# ing916 register map
Vendor: INGChips; Series: ing916xx; File version: 522
CPU: CM4 r0p1, little endian, MPU, FPU, VTOR, 5 interrupt priority bits
Registers are 32-bit, read-write, reset 0x0 unless marked. A register's access mark holds for its fields unless they carry their own. Offsets are from the block's base; [hi:lo] are bit positions; {n}, {i} and the like mark numbered series.

## usbc
Base 0x40180000
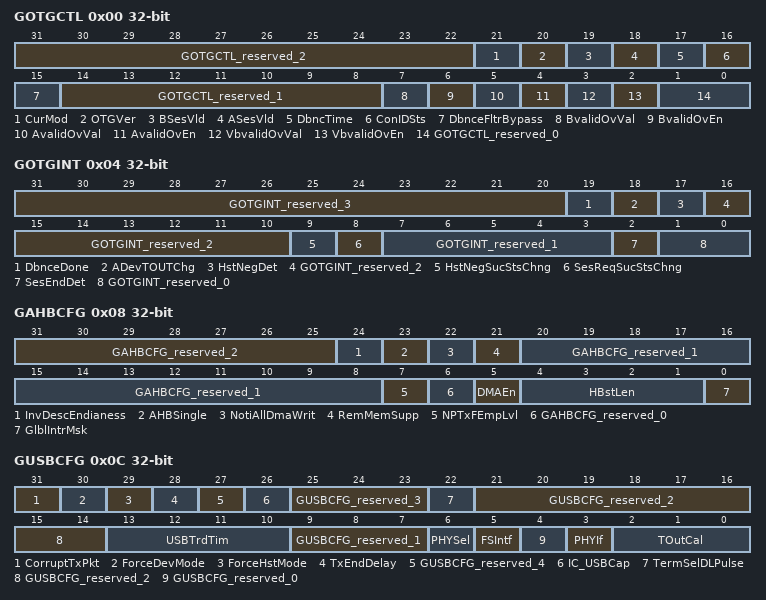
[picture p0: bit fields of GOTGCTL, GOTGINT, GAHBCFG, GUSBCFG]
0x00 GOTGCTL — reg description:
  [31:22] GOTGCTL_reserved_2 — reg description:
  [21] CurMod — reg description:
  [20] OTGVer — reg description:
  [19] BSesVld — reg description:
  [18] ASesVld — reg description:
  [17] DbncTime — reg description:
  [16] ConIDSts — reg description:
  [15] DbnceFltrBypass — reg description:
  [14:8] GOTGCTL_reserved_1 — reg description:
  [7] BvalidOvVal — reg description:
  [6] BvalidOvEn — reg description:
  [5] AvalidOvVal — reg description:
  [4] AvalidOvEn — reg description:
  [3] VbvalidOvVal — reg description:
  [2] VbvalidOvEn — reg description:
  [1:0] GOTGCTL_reserved_0 — reg description:
0x04 GOTGINT — reg description:
  [31:20] GOTGINT_reserved_3 — reg description:
  [19] DbnceDone — reg description:
  [18] ADevTOUTChg — reg description:
  [17] HstNegDet — reg description:
  [16:10] GOTGINT_reserved_2 — reg description:
  [9] HstNegSucStsChng — reg description:
  [8] SesReqSucStsChng — reg description:
  [7:3] GOTGINT_reserved_1 — reg description:
  [2] SesEndDet — reg description:
  [1:0] GOTGINT_reserved_0 — reg description:
0x08 GAHBCFG — reg description:
  [31:25] GAHBCFG_reserved_2 — reg description:
  [24] InvDescEndianess — reg description:
  [23] AHBSingle — reg description:
  [22] NotiAllDmaWrit — reg description:
  [21] RemMemSupp — reg description:
  [20:8] GAHBCFG_reserved_1 — reg description:
  [7] NPTxFEmpLvl — reg description:
  [6] GAHBCFG_reserved_0 — reg description:
  [5] DMAEn — reg description:
  [4:1] HBstLen — reg description:
  [0] GlblIntrMsk — reg description:
0x0C GUSBCFG — reg description:
  [31] CorruptTxPkt — reg description:
  [30] ForceDevMode — reg description:
  [29] ForceHstMode — reg description:
  [28] TxEndDelay — reg description:
  [27] GUSBCFG_reserved_4 — reg description:
  [26] IC_USBCap — reg description:
  [25:23] GUSBCFG_reserved_3 — reg description:
  [22] TermSelDLPulse — reg description:
  [21:14] GUSBCFG_reserved_2 — reg description:
  [13:10] USBTrdTim — reg description:
  [9:7] GUSBCFG_reserved_1 — reg description:
  [6] PHYSel — reg description:
  [5] FSIntf — reg description:
  [4] GUSBCFG_reserved_0 — reg description:
  [3] PHYIf — reg description:
  [2:0] TOutCal — reg description:
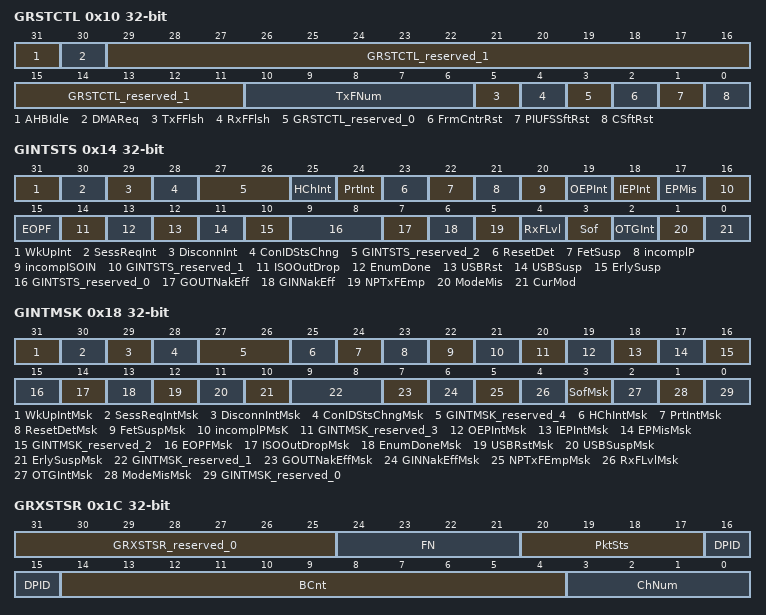
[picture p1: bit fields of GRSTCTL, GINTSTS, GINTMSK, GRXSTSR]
0x10 GRSTCTL — reg description:
  [31] AHBIdle — reg description:
  [30] DMAReq — reg description:
  [29:11] GRSTCTL_reserved_1 — reg description:
  [10:6] TxFNum — reg description:
  [5] TxFFlsh — reg description:
  [4] RxFFlsh — reg description:
  [3] GRSTCTL_reserved_0 — reg description:
  [2] FrmCntrRst — reg description:
  [1] PIUFSSftRst — reg description:
  [0] CSftRst — reg description:
0x14 GINTSTS — reg description:
  [31] WkUpInt — reg description:
  [30] SessReqInt — reg description:
  [29] DisconnInt — reg description:
  [28] ConIDStsChng — reg description:
  [27:26] GINTSTS_reserved_2 — reg description:
  [25] HChInt — reg description:
  [24] PrtInt — reg description:
  [23] ResetDet — reg description:
  [22] FetSusp — reg description:
  [21] incomplP — reg description:
  [20] incompISOIN — reg description:
  [19] OEPInt — reg description:
  [18] IEPInt — reg description:
  [17] EPMis — reg description:
  [16] GINTSTS_reserved_1 — reg description:
  [15] EOPF — reg description:
  [14] ISOOutDrop — reg description:
  [13] EnumDone — reg description:
  [12] USBRst — reg description:
  [11] USBSusp — reg description:
  [10] ErlySusp — reg description:
  [9:8] GINTSTS_reserved_0 — reg description:
  [7] GOUTNakEff — reg description:
  [6] GINNakEff — reg description:
  [5] NPTxFEmp — reg description:
  [4] RxFLvl — reg description:
  [3] Sof — reg description:
  [2] OTGInt — reg description:
  [1] ModeMis — reg description:
  [0] CurMod — reg description:
0x18 GINTMSK — reg description:
  [31] WkUpIntMsk — reg description:
  [30] SessReqIntMsk — reg description:
  [29] DisconnIntMsk — reg description:
  [28] ConIDStsChngMsk — reg description:
  [27:26] GINTMSK_reserved_4 — reg description:
  [25] HChIntMsk — reg description:
  [24] PrtIntMsk — reg description:
  [23] ResetDetMsk — reg description:
  [22] FetSuspMsk — reg description:
  [21] incomplPMsK — reg description:
  [20] GINTMSK_reserved_3 — reg description:
  [19] OEPIntMsk — reg description:
  [18] IEPIntMsk — reg description:
  [17] EPMisMsk — reg description:
  [16] GINTMSK_reserved_2 — reg description:
  [15] EOPFMsk — reg description:
  [14] ISOOutDropMsk — reg description:
  [13] EnumDoneMsk — reg description:
  [12] USBRstMsk — reg description:
  [11] USBSuspMsk — reg description:
  [10] ErlySuspMsk — reg description:
  [9:8] GINTMSK_reserved_1 — reg description:
  [7] GOUTNakEffMsk — reg description:
  [6] GINNakEffMsk — reg description:
  [5] NPTxFEmpMsk — reg description:
  [4] RxFLvlMsk — reg description:
  [3] SofMsk — reg description:
  [2] OTGIntMsk — reg description:
  [1] ModeMisMsk — reg description:
  [0] GINTMSK_reserved_0 — reg description:
0x1C GRXSTSR — reg description:
  [31:25] GRXSTSR_reserved_0 — reg description:
  [24:21] FN — reg description:
  [20:17] PktSts — reg description:
  [16:15] DPID — reg description:
  [14:4] BCnt — reg description:
  [3:0] ChNum — reg description:
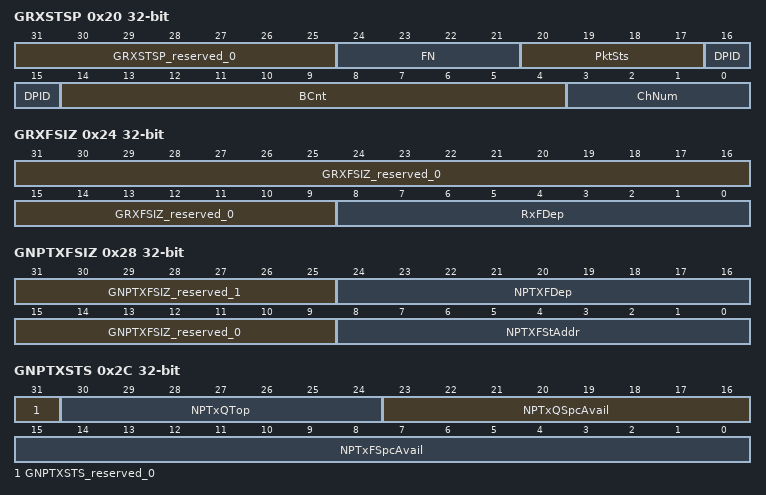
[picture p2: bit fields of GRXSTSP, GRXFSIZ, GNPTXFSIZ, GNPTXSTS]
0x20 GRXSTSP — reg description:
  [31:25] GRXSTSP_reserved_0 — reg description:
  [24:21] FN — reg description:
  [20:17] PktSts — reg description:
  [16:15] DPID — reg description:
  [14:4] BCnt — reg description:
  [3:0] ChNum — reg description:
0x24 GRXFSIZ — reg description:
  [31:9] GRXFSIZ_reserved_0 — reg description:
  [8:0] RxFDep — reg description:
0x28 GNPTXFSIZ — reg description:
  [31:25] GNPTXFSIZ_reserved_1 — reg description:
  [24:16] NPTXFDep — reg description:
  [15:9] GNPTXFSIZ_reserved_0 — reg description:
  [8:0] NPTXFStAddr — reg description:
0x2C GNPTXSTS — reg description:
  [31] GNPTXSTS_reserved_0 — reg description:
  [30:24] NPTxQTop — reg description:
  [23:16] NPTxQSpcAvail — reg description:
  [15:0] NPTxFSpcAvail — reg description:
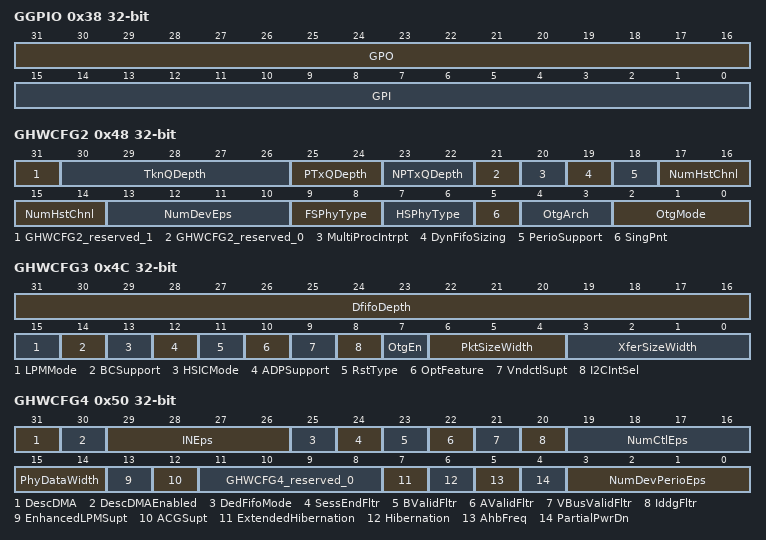
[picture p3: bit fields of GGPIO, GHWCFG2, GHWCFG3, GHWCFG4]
0x38 GGPIO — reg description:
  [31:16] GPO — reg description:
  [15:0] GPI — reg description:
0x3C GUID — reg description:
0x40 GSNPSID — reg description:
  [31:0] SynopsysID
0x44 GHWCFG1 — reg description:
  [31:0] EpDir
0x48 GHWCFG2 — reg description:
  [31] GHWCFG2_reserved_1 — reg description:
  [30:26] TknQDepth — reg description:
  [25:24] PTxQDepth — reg description:
  [23:22] NPTxQDepth — reg description:
  [21] GHWCFG2_reserved_0 — reg description:
  [20] MultiProcIntrpt — reg description:
  [19] DynFifoSizing — reg description:
  [18] PerioSupport — reg description:
  [17:14] NumHstChnl — reg description:
  [13:10] NumDevEps — reg description:
  [9:8] FSPhyType — reg description:
  [7:6] HSPhyType — reg description:
  [5] SingPnt — reg description:
  [4:3] OtgArch — reg description:
  [2:0] OtgMode — reg description:
0x4C GHWCFG3 — reg description:
  [31:16] DfifoDepth — reg description:
  [15] LPMMode — reg description:
  [14] BCSupport — reg description:
  [13] HSICMode — reg description:
  [12] ADPSupport — reg description:
  [11] RstType — reg description:
  [10] OptFeature — reg description:
  [9] VndctlSupt — reg description:
  [8] I2CIntSel — reg description:
  [7] OtgEn — reg description:
  [6:4] PktSizeWidth — reg description:
  [3:0] XferSizeWidth — reg description:
0x50 GHWCFG4 — reg description:
  [31] DescDMA — reg description:
  [30] DescDMAEnabled — reg description:
  [29:26] INEps — reg description:
  [25] DedFifoMode — reg description:
  [24] SessEndFltr — reg description:
  [23] BValidFltr — reg description:
  [22] AValidFltr — reg description:
  [21] VBusValidFltr — reg description:
  [20] IddgFltr — reg description:
  [19:16] NumCtlEps — reg description:
  [15:14] PhyDataWidth — reg description:
  [13] EnhancedLPMSupt — reg description:
  [12] ACGSupt — reg description:
  [11:8] GHWCFG4_reserved_0 — reg description:
  [7] ExtendedHibernation — reg description:
  [6] Hibernation — reg description:
  [5] AhbFreq — reg description:
  [4] PartialPwrDn — reg description:
  [3:0] NumDevPerioEps — reg description:
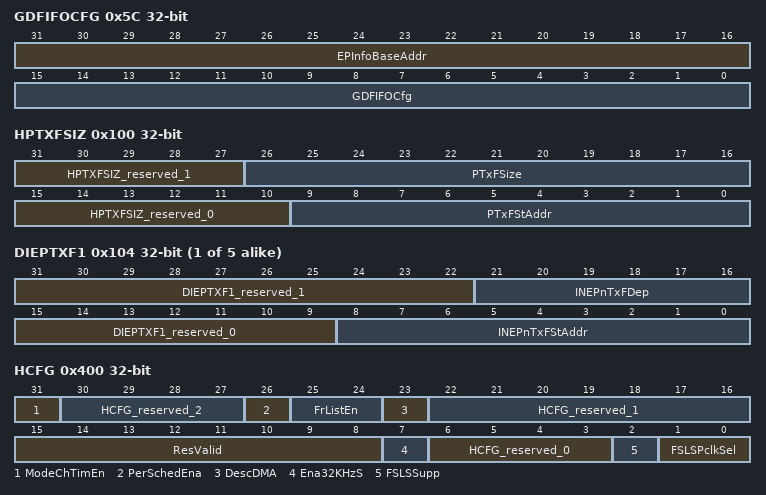
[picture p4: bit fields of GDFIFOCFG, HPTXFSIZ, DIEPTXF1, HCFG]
0x5C GDFIFOCFG — reg description:
  [31:16] EPInfoBaseAddr — reg description:
  [15:0] GDFIFOCfg — reg description:
0x100 HPTXFSIZ — reg description:
  [31:27] HPTXFSIZ_reserved_1 — reg description:
  [26:16] PTxFSize — reg description:
  [15:10] HPTXFSIZ_reserved_0 — reg description:
  [9:0] PTxFStAddr — reg description:
{0x100+4i} DIEPTXF{i} (i=1..5) — reg description:
  [31:22] DIEPTXF{i}_reserved_1 — reg description:
  [21:16] INEPnTxFDep — reg description:
  [15:9] DIEPTXF{i}_reserved_0 — reg description:
  [8:0] INEPnTxFStAddr — reg description:
0x400 HCFG — reg description:
  [31] ModeChTimEn — reg description:
  [30:27] HCFG_reserved_2 — reg description:
  [26] PerSchedEna — reg description:
  [25:24] FrListEn — reg description:
  [23] DescDMA — reg description:
  [22:16] HCFG_reserved_1 — reg description:
  [15:8] ResValid — reg description:
  [7] Ena32KHzS — reg description:
  [6:3] HCFG_reserved_0 — reg description:
  [2] FSLSSupp — reg description:
  [1:0] FSLSPclkSel — reg description:
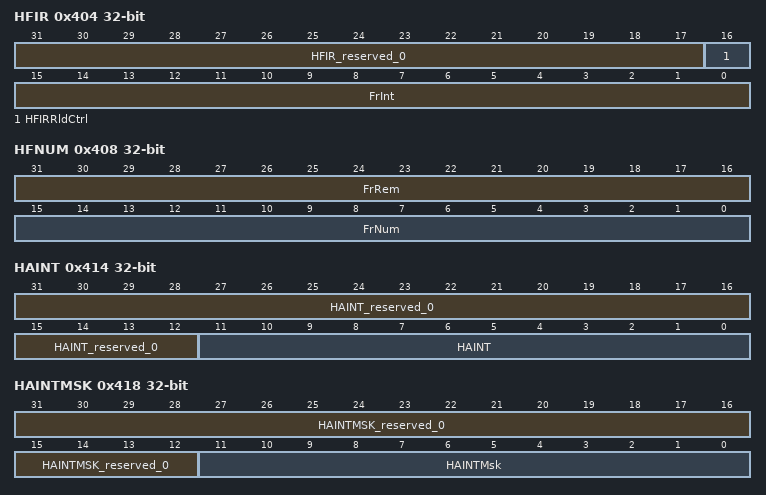
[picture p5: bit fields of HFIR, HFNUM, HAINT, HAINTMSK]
0x404 HFIR — reg description:
  [31:17] HFIR_reserved_0 — reg description:
  [16] HFIRRldCtrl — reg description:
  [15:0] FrInt — reg description:
0x408 HFNUM — reg description:
  [31:16] FrRem — reg description:
  [15:0] FrNum — reg description:
0x414 HAINT — reg description:
  [31:12] HAINT_reserved_0 — reg description:
  [11:0] HAINT — reg description:
0x418 HAINTMSK — reg description:
  [31:12] HAINTMSK_reserved_0 — reg description:
  [11:0] HAINTMsk — reg description:
0x41C HFLBAddr — reg description:
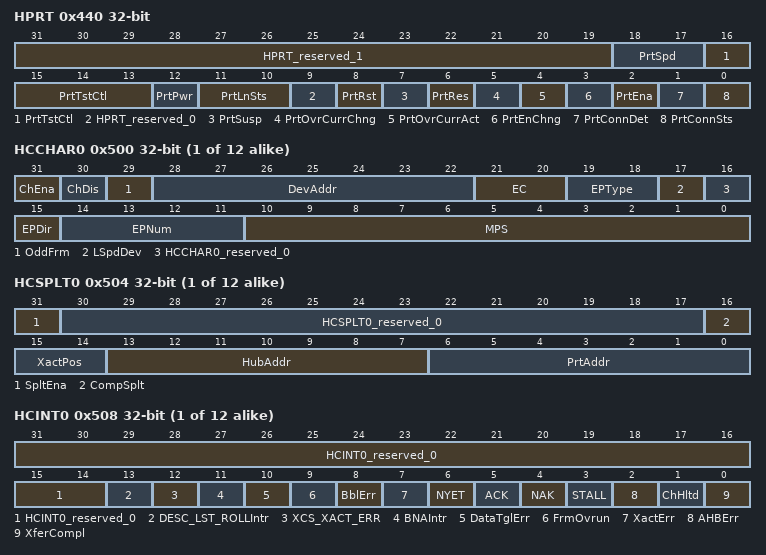
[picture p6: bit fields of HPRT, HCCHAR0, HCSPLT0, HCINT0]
0x440 HPRT — reg description:
  [31:19] HPRT_reserved_1 — reg description:
  [18:17] PrtSpd — reg description:
  [16:13] PrtTstCtl — reg description:
  [12] PrtPwr — reg description:
  [11:10] PrtLnSts — reg description:
  [9] HPRT_reserved_0 — reg description:
  [8] PrtRst — reg description:
  [7] PrtSusp — reg description:
  [6] PrtRes — reg description:
  [5] PrtOvrCurrChng — reg description:
  [4] PrtOvrCurrAct — reg description:
  [3] PrtEnChng — reg description:
  [2] PrtEna — reg description:
  [1] PrtConnDet — reg description:
  [0] PrtConnSts — reg description:
{0x500+0x20*i} HCCHAR{i} (i=0..11) — reg description:
  [31] ChEna — reg description:
  [30] ChDis — reg description:
  [29] OddFrm — reg description:
  [28:22] DevAddr — reg description:
  [21:20] EC — reg description:
  [19:18] EPType — reg description:
  [17] LSpdDev — reg description:
  [16] HCCHAR{i}_reserved_0 — reg description:
  [15] EPDir — reg description:
  [14:11] EPNum — reg description:
  [10:0] MPS — reg description:
{0x504+0x20*i} HCSPLT{i} (i=0..11) — reg description:
  [31] SpltEna — reg description:
  [30:17] HCSPLT{i}_reserved_0 — reg description:
  [16] CompSplt — reg description:
  [15:14] XactPos — reg description:
  [13:7] HubAddr — reg description:
  [6:0] PrtAddr — reg description:
{0x508+0x20*i} HCINT{i} (i=0..11) — reg description:
  [31:14] HCINT{i}_reserved_0 — reg description:
  [13] DESC_LST_ROLLIntr — reg description:
  [12] XCS_XACT_ERR — reg description:
  [11] BNAIntr — reg description:
  [10] DataTglErr — reg description:
  [9] FrmOvrun — reg description:
  [8] BblErr — reg description:
  [7] XactErr — reg description:
  [6] NYET — reg description:
  [5] ACK — reg description:
  [4] NAK — reg description:
  [3] STALL — reg description:
  [2] AHBErr — reg description:
  [1] ChHltd — reg description:
  [0] XferCompl — reg description:
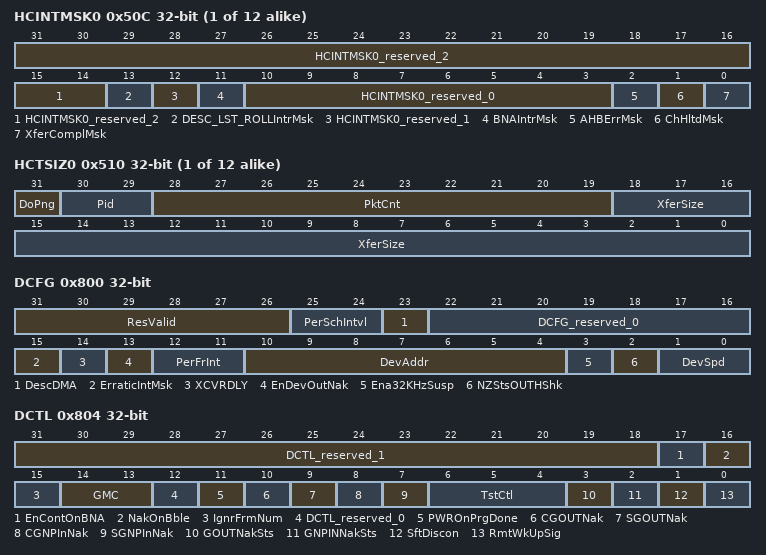
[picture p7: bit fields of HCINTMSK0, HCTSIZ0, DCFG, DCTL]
{0x50C+0x20*i} HCINTMSK{i} (i=0..11) — reg description:
  [31:14] HCINTMSK{i}_reserved_2 — reg description:
  [13] DESC_LST_ROLLIntrMsk — reg description:
  [12] HCINTMSK{i}_reserved_1 — reg description:
  [11] BNAIntrMsk — reg description:
  [10:3] HCINTMSK{i}_reserved_0 — reg description:
  [2] AHBErrMsk — reg description:
  [1] ChHltdMsk — reg description:
  [0] XferComplMsk — reg description:
{0x510+0x20*i} HCTSIZ{i} (i=0..11) — reg description:
  [31] DoPng — reg description:
  [30:29] Pid — reg description:
  [28:19] PktCnt — reg description:
  [18:0] XferSize — reg description:
{0x514+0x20*i} HCDMA{i} (i=0..11) — reg description:
  [31:0] DMAAddr
{0x51C+0x20*i} HCDMAB{i} (i=0..11) — reg description:
  [31:0] HCDMAB
0x800 DCFG — reg description:
  [31:26] ResValid — reg description:
  [25:24] PerSchIntvl — reg description:
  [23] DescDMA — reg description:
  [22:16] DCFG_reserved_0 — reg description:
  [15] ErraticIntMsk — reg description:
  [14] XCVRDLY — reg description:
  [13] EnDevOutNak — reg description:
  [12:11] PerFrInt — reg description:
  [10:4] DevAddr — reg description:
  [3] Ena32KHzSusp — reg description:
  [2] NZStsOUTHShk — reg description:
  [1:0] DevSpd — reg description:
0x804 DCTL — reg description:
  [31:18] DCTL_reserved_1 — reg description:
  [17] EnContOnBNA — reg description:
  [16] NakOnBble — reg description:
  [15] IgnrFrmNum — reg description:
  [14:13] GMC — reg description:
  [12] DCTL_reserved_0 — reg description:
  [11] PWROnPrgDone — reg description:
  [10] CGOUTNak — reg description:
  [9] SGOUTNak — reg description:
  [8] CGNPInNak — reg description:
  [7] SGNPInNak — reg description:
  [6:4] TstCtl — reg description:
  [3] GOUTNakSts — reg description:
  [2] GNPINNakSts — reg description:
  [1] SftDiscon — reg description:
  [0] RmtWkUpSig — reg description:
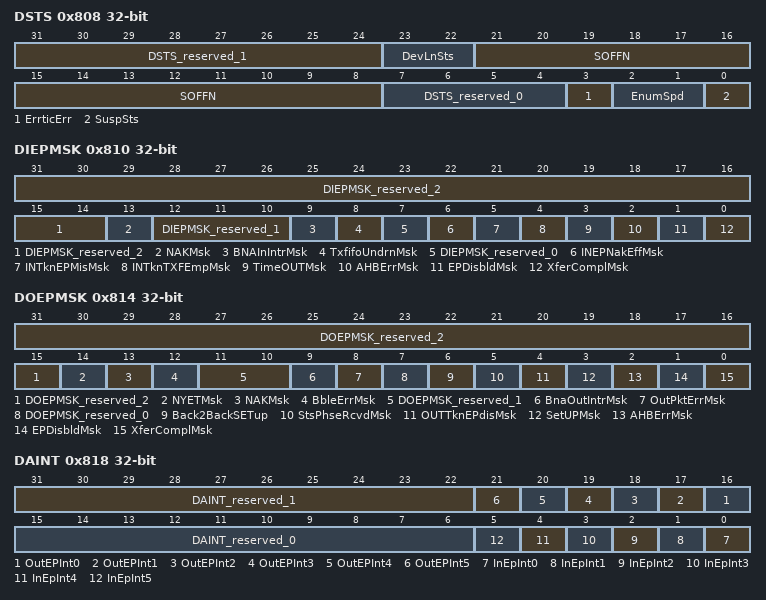
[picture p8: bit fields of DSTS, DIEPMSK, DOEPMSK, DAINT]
0x808 DSTS — reg description:
  [31:24] DSTS_reserved_1 — reg description:
  [23:22] DevLnSts — reg description:
  [21:8] SOFFN — reg description:
  [7:4] DSTS_reserved_0 — reg description:
  [3] ErrticErr — reg description:
  [2:1] EnumSpd — reg description:
  [0] SuspSts — reg description:
0x810 DIEPMSK — reg description:
  [31:14] DIEPMSK_reserved_2 — reg description:
  [13] NAKMsk — reg description:
  [12:10] DIEPMSK_reserved_1 — reg description:
  [9] BNAInIntrMsk — reg description:
  [8] TxfifoUndrnMsk — reg description:
  [7] DIEPMSK_reserved_0 — reg description:
  [6] INEPNakEffMsk — reg description:
  [5] INTknEPMisMsk — reg description:
  [4] INTknTXFEmpMsk — reg description:
  [3] TimeOUTMsk — reg description:
  [2] AHBErrMsk — reg description:
  [1] EPDisbldMsk — reg description:
  [0] XferComplMsk — reg description:
0x814 DOEPMSK — reg description:
  [31:15] DOEPMSK_reserved_2 — reg description:
  [14] NYETMsk — reg description:
  [13] NAKMsk — reg description:
  [12] BbleErrMsk — reg description:
  [11:10] DOEPMSK_reserved_1 — reg description:
  [9] BnaOutIntrMsk — reg description:
  [8] OutPktErrMsk — reg description:
  [7] DOEPMSK_reserved_0 — reg description:
  [6] Back2BackSETup — reg description:
  [5] StsPhseRcvdMsk — reg description:
  [4] OUTTknEPdisMsk — reg description:
  [3] SetUPMsk — reg description:
  [2] AHBErrMsk — reg description:
  [1] EPDisbldMsk — reg description:
  [0] XferComplMsk — reg description:
0x818 DAINT — reg description:
  [31:22] DAINT_reserved_1 — reg description:
  [n+16] OutEPInt{n} (n=0..5) — reg description:
  [15:6] DAINT_reserved_0 — reg description:
  [n] InEpInt{n} (n=0..5) — reg description:
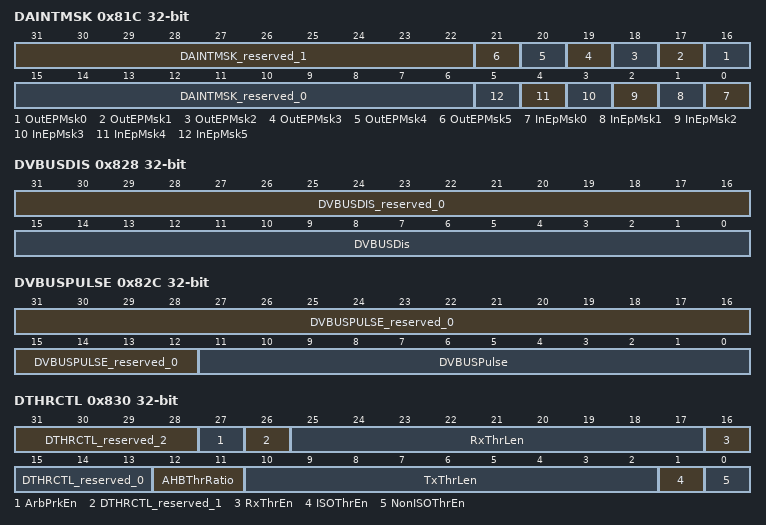
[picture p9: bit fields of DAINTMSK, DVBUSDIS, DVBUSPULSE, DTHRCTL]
0x81C DAINTMSK — reg description:
  [31:22] DAINTMSK_reserved_1 — reg description:
  [n+16] OutEPMsk{n} (n=0..5) — reg description:
  [15:6] DAINTMSK_reserved_0 — reg description:
  [n] InEpMsk{n} (n=0..5) — reg description:
0x828 DVBUSDIS — reg description:
  [31:16] DVBUSDIS_reserved_0 — reg description:
  [15:0] DVBUSDis — reg description:
0x82C DVBUSPULSE — reg description:
  [31:12] DVBUSPULSE_reserved_0 — reg description:
  [11:0] DVBUSPulse — reg description:
0x830 DTHRCTL — reg description:
  [31:28] DTHRCTL_reserved_2 — reg description:
  [27] ArbPrkEn — reg description:
  [26] DTHRCTL_reserved_1 — reg description:
  [25:17] RxThrLen — reg description:
  [16] RxThrEn — reg description:
  [15:13] DTHRCTL_reserved_0 — reg description:
  [12:11] AHBThrRatio — reg description:
  [10:2] TxThrLen — reg description:
  [1] ISOThrEn — reg description:
  [0] NonISOThrEn — reg description:
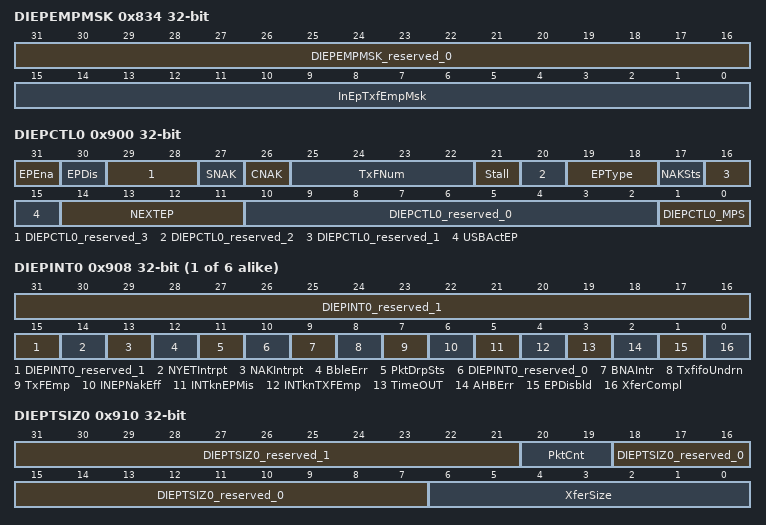
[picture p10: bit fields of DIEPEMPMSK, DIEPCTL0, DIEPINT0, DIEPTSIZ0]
0x834 DIEPEMPMSK — reg description:
  [31:16] DIEPEMPMSK_reserved_0 — reg description:
  [15:0] InEpTxfEmpMsk — reg description:
0x900 DIEPCTL0 — reg description:
  [31] EPEna — reg description:
  [30] EPDis — reg description:
  [29:28] DIEPCTL0_reserved_3 — reg description:
  [27] SNAK — reg description:
  [26] CNAK — reg description:
  [25:22] TxFNum — reg description:
  [21] Stall — reg description:
  [20] DIEPCTL0_reserved_2 — reg description:
  [19:18] EPType — reg description:
  [17] NAKSts — reg description:
  [16] DIEPCTL0_reserved_1 — reg description:
  [15] USBActEP — reg description:
  [14:11] NEXTEP — reg description:
  [10:2] DIEPCTL0_reserved_0 — reg description:
  [1:0] DIEPCTL0_MPS — reg description:
{0x908+0x20*i} DIEPINT{i} (i=0..5) — reg description:
  [31:15] DIEPINT{i}_reserved_1 — reg description:
  [14] NYETIntrpt — reg description:
  [13] NAKIntrpt — reg description:
  [12] BbleErr — reg description:
  [11] PktDrpSts — reg description:
  [10] DIEPINT{i}_reserved_0 — reg description:
  [9] BNAIntr — reg description:
  [8] TxfifoUndrn — reg description:
  [7] TxFEmp — reg description:
  [6] INEPNakEff — reg description:
  [5] INTknEPMis — reg description:
  [4] INTknTXFEmp — reg description:
  [3] TimeOUT — reg description:
  [2] AHBErr — reg description:
  [1] EPDisbld — reg description:
  [0] XferCompl — reg description:
0x910 DIEPTSIZ0 — reg description:
  [31:21] DIEPTSIZ0_reserved_1 — reg description:
  [20:19] PktCnt — reg description:
  [18:7] DIEPTSIZ0_reserved_0 — reg description:
  [6:0] XferSize — reg description:
{0x914+0x20*i} DIEPDMA{i} (i=0..5) — reg description:
  [31:0] DMAAddr
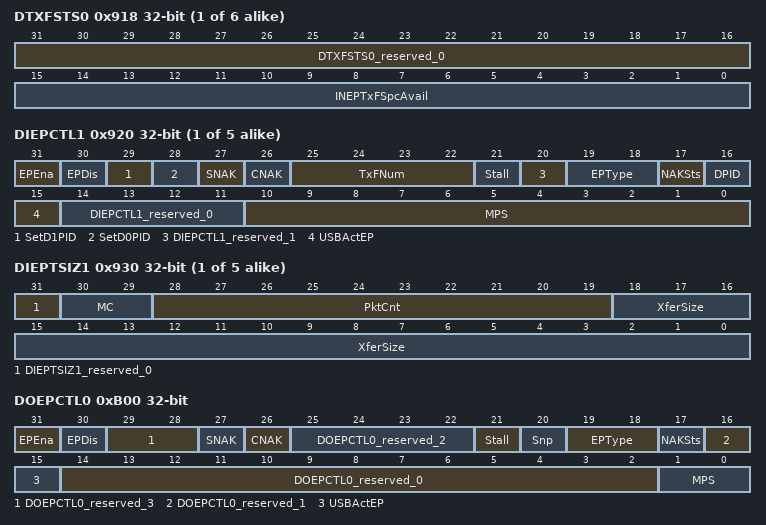
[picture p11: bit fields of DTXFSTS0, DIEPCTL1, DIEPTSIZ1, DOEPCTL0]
{0x918+0x20*i} DTXFSTS{i} (i=0..5) — reg description:
  [31:16] DTXFSTS{i}_reserved_0 — reg description:
  [15:0] INEPTxFSpcAvail — reg description:
{0x91C+0x20*i} DIEPDMAB{i} (i=0..5) — reg description:
  [31:0] DMABufferAddr
{0x900+0x20*i} DIEPCTL{i} (i=1..5) — reg description:
  [31] EPEna — reg description:
  [30] EPDis — reg description:
  [29] SetD1PID — reg description:
  [28] SetD0PID — reg description:
  [27] SNAK — reg description:
  [26] CNAK — reg description:
  [25:22] TxFNum — reg description:
  [21] Stall — reg description:
  [20] DIEPCTL{i}_reserved_1 — reg description:
  [19:18] EPType — reg description:
  [17] NAKSts — reg description:
  [16] DPID — reg description:
  [15] USBActEP — reg description:
  [14:11] DIEPCTL{i}_reserved_0 — reg description:
  [10:0] MPS — reg description:
{0x910+0x20*i} DIEPTSIZ{i} (i=1..5) — reg description:
  [31] DIEPTSIZ{i}_reserved_0 — reg description:
  [30:29] MC — reg description:
  [28:19] PktCnt — reg description:
  [18:0] XferSize — reg description:
0xB00 DOEPCTL0 — reg description:
  [31] EPEna — reg description:
  [30] EPDis — reg description:
  [29:28] DOEPCTL0_reserved_3 — reg description:
  [27] SNAK — reg description:
  [26] CNAK — reg description:
  [25:22] DOEPCTL0_reserved_2 — reg description:
  [21] Stall — reg description:
  [20] Snp — reg description:
  [19:18] EPType — reg description:
  [17] NAKSts — reg description:
  [16] DOEPCTL0_reserved_1 — reg description:
  [15] USBActEP — reg description:
  [14:2] DOEPCTL0_reserved_0 — reg description:
  [1:0] MPS — reg description:
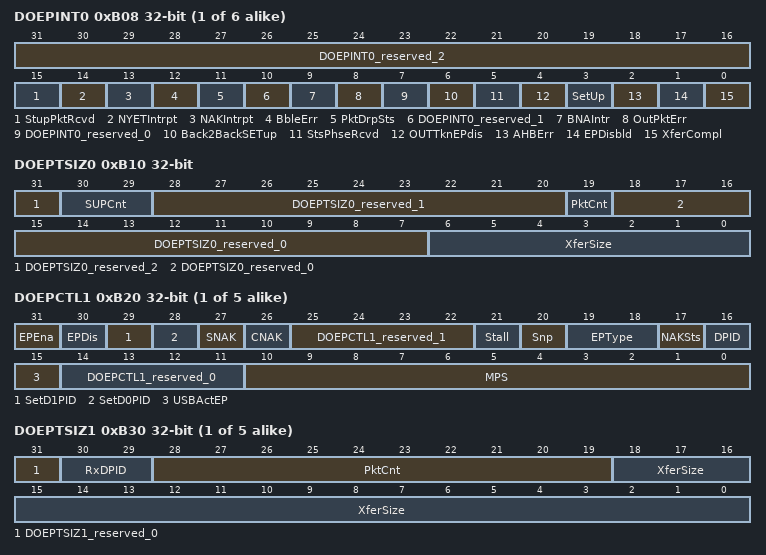
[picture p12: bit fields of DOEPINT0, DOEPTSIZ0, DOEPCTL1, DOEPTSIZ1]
{0xB08+0x20*i} DOEPINT{i} (i=0..5) — reg description:
  [31:16] DOEPINT{i}_reserved_2 — reg description:
  [15] StupPktRcvd — reg description:
  [14] NYETIntrpt — reg description:
  [13] NAKIntrpt — reg description:
  [12] BbleErr — reg description:
  [11] PktDrpSts — reg description:
  [10] DOEPINT{i}_reserved_1 — reg description:
  [9] BNAIntr — reg description:
  [8] OutPktErr — reg description:
  [7] DOEPINT{i}_reserved_0 — reg description:
  [6] Back2BackSETup — reg description:
  [5] StsPhseRcvd — reg description:
  [4] OUTTknEPdis — reg description:
  [3] SetUp — reg description:
  [2] AHBErr — reg description:
  [1] EPDisbld — reg description:
  [0] XferCompl — reg description:
0xB10 DOEPTSIZ0 — reg description:
  [31] DOEPTSIZ0_reserved_2 — reg description:
  [30:29] SUPCnt — reg description:
  [28:20] DOEPTSIZ0_reserved_1 — reg description:
  [19] PktCnt — reg description:
  [18:7] DOEPTSIZ0_reserved_0 — reg description:
  [6:0] XferSize — reg description:
{0xB14+0x20*i} DOEPDMA{i} (i=0..5) — reg description:
  [31:0] DMAAddr
{0xB1C+0x20*i} DOEPDMAB{i} (i=0..5) — reg description:
  [31:0] DMABufferAddr
{0xB00+0x20*i} DOEPCTL{i} (i=1..5) — reg description:
  [31] EPEna — reg description:
  [30] EPDis — reg description:
  [29] SetD1PID — reg description:
  [28] SetD0PID — reg description:
  [27] SNAK — reg description:
  [26] CNAK — reg description:
  [25:22] DOEPCTL{i}_reserved_1 — reg description:
  [21] Stall — reg description:
  [20] Snp — reg description:
  [19:18] EPType — reg description:
  [17] NAKSts — reg description:
  [16] DPID — reg description:
  [15] USBActEP — reg description:
  [14:11] DOEPCTL{i}_reserved_0 — reg description:
  [10:0] MPS — reg description:
{0xB10+0x20*i} DOEPTSIZ{i} (i=1..5) — reg description:
  [31] DOEPTSIZ{i}_reserved_0 — reg description:
  [30:29] RxDPID — reg description:
  [28:19] PktCnt — reg description:
  [18:0] XferSize — reg description:
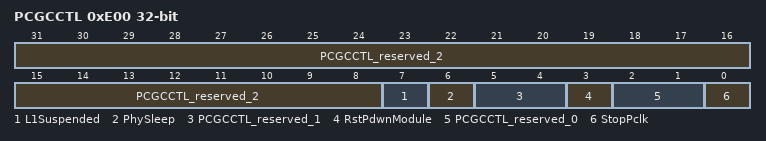
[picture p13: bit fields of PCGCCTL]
0xE00 PCGCCTL — reg description:
  [31:8] PCGCCTL_reserved_2 — reg description:
  [7] L1Suspended — reg description:
  [6] PhySleep — reg description:
  [5:4] PCGCCTL_reserved_1 — reg description:
  [3] RstPdwnModule — reg description:
  [2:1] PCGCCTL_reserved_0 — reg description:
  [0] StopPclk — reg description:
